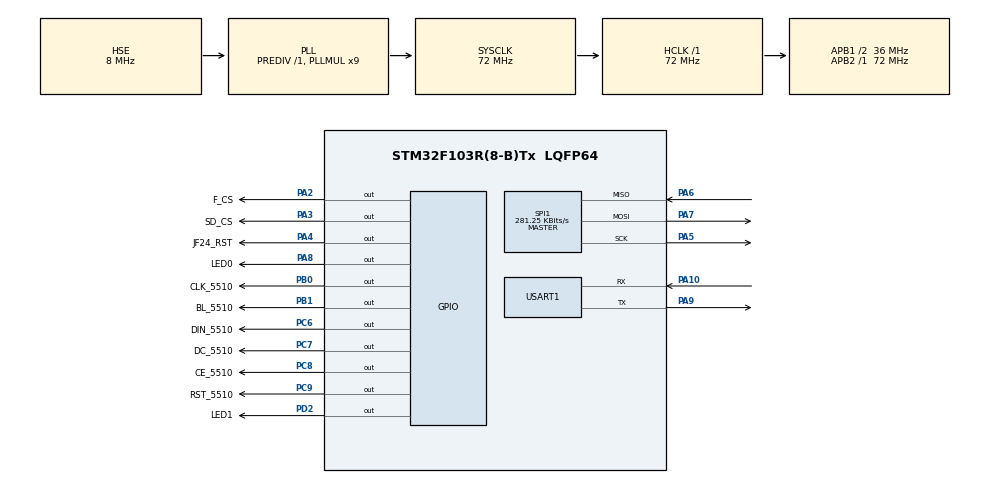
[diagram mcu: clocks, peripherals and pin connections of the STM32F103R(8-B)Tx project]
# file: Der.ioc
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FREERTOS.Tasks01=Task_LED,0,128,Task_Func,Default
Mcu.Family=STM32F1
Mcu.Name=STM32F103R(8-B)Tx
Mcu.Package=LQFP64
NVIC.PriorityGroup=NVIC_PRIORITYGROUP_4
NVIC.TIM4_IRQn=true\:0\:0\:false\:false\:true\:false
NVIC.TimeBase=TIM4_IRQn
NVIC.TimeBaseIP=TIM4
NVIC.USART1_IRQn=true\:0\:0\:false\:false\:true\:false
PA10.Mode=Asynchronous
PA10.Signal=USART1_RX
PA2.GPIO_Label=F_CS
PA2.PinState=GPIO_PIN_SET
PA2.Signal=GPIO_Output
PA3.GPIO_Label=SD_CS
PA3.PinState=GPIO_PIN_SET
PA3.Signal=GPIO_Output
PA4.GPIO_Label=JF24_RST
PA4.PinState=GPIO_PIN_SET
PA4.Signal=GPIO_Output
PA5.Mode=Full_Duplex_Master
PA5.Signal=SPI1_SCK
PA6.Mode=Full_Duplex_Master
PA6.Signal=SPI1_MISO
PA7.Mode=Full_Duplex_Master
PA7.Signal=SPI1_MOSI
PA8.GPIO_Label=LED0
PA8.Signal=GPIO_Output
PA9.Mode=Asynchronous
PA9.Signal=USART1_TX
PB0.GPIO_Label=CLK_5510
PB0.Signal=GPIO_Output
PB1.GPIO_Label=BL_5510
PB1.Signal=GPIO_Output
PC6.GPIO_Label=DIN_5510
PC6.Signal=GPIO_Output
PC7.GPIO_Label=DC_5510
PC7.Signal=GPIO_Output
PC8.GPIO_Label=CE_5510
PC8.Signal=GPIO_Output
PC9.GPIO_Label=RST_5510
PC9.Signal=GPIO_Output
PD0-OSC_IN.Mode=HSE-External-Oscillator
PD0-OSC_IN.Signal=RCC_OSC_IN
PD1-OSC_OUT.Mode=HSE-External-Oscillator
PD1-OSC_OUT.Signal=RCC_OSC_OUT
PD2.GPIO_Label=LED1
PD2.Signal=GPIO_Output
ProjectManager.HeapSize=0x200
ProjectManager.StackSize=0x400
ProjectManager.TargetToolchain=MDK-ARM V5
RCC.AHBFreq_Value=72000000
RCC.APB1CLKDivider=RCC_HCLK_DIV2
RCC.APB1Freq_Value=36000000
RCC.APB1TimFreq_Value=72000000
RCC.APB2Freq_Value=72000000
RCC.APB2TimFreq_Value=72000000
RCC.HCLKFreq_Value=72000000
RCC.HSIState=RCC_HSI_ON
RCC.PLLMUL=RCC_PLL_MUL9
RCC.PLLSourceVirtual=RCC_PLLSOURCE_HSE
RCC.SYSCLKFreq_VALUE=72000000
RCC.SYSCLKSource=RCC_SYSCLKSOURCE_PLLCLK
RCC.USBFreq_Value=72000000
SPI1.BaudRatePrescaler=SPI_BAUDRATEPRESCALER_256
SPI1.CLKPhase=SPI_PHASE_2EDGE
SPI1.CLKPolarity=SPI_POLARITY_HIGH
SPI1.CRCCalculation=SPI_CRCCALCULATION_DISABLE
SPI1.CalculateBaudRate=281.25 KBits/s
SPI1.Mode=SPI_MODE_MASTER
VP_FATFS_VS_Generic.Mode=User_defined
VP_FREERTOS_VS_ENABLE.Mode=Enabled
VP_SYS_VS_ND.Mode=No_Debug
VP_SYS_VS_tim4.Mode=TIM4
board=Der

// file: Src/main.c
/**
  ******************************************************************************
  * File Name          : main.c
  * Description        : Main program body
  ******************************************************************************
  *
  * Copyright (c) 2017 STMicroelectronics International N.V.
  * All rights reserved.
  *
  * Redistribution and use in source and binary forms, with or without
  * modification, are permitted, provided that the following conditions are met:
  *
  * 1. Redistribution of source code must retain the above copyright notice,
  *    this list of conditions and the following disclaimer.
  * 2. Redistributions in binary form must reproduce the above copyright notice,
  *    this list of conditions and the following disclaimer in the documentation
  *    and/or other materials provided with the distribution.
  * 3. Neither the name of STMicroelectronics nor the names of other
  *    contributors to this software may be used to endorse or promote products
  *    derived from this software without specific written permission.
  * 4. This software, including modifications and/or derivative works of this
  *    software, must execute solely and exclusively on microcontroller or
  *    microprocessor devices manufactured by or for STMicroelectronics.
  * 5. Redistribution and use of this software other than as permitted under
  *    this license is void and will automatically terminate your rights under
  *    this license.
  *
  * THIS SOFTWARE IS PROVIDED BY STMICROELECTRONICS AND CONTRIBUTORS "AS IS"
  * AND ANY EXPRESS, IMPLIED OR STATUTORY WARRANTIES, INCLUDING, BUT NOT
  * LIMITED TO, THE IMPLIED WARRANTIES OF MERCHANTABILITY, FITNESS FOR A
  * PARTICULAR PURPOSE AND NON-INFRINGEMENT OF THIRD PARTY INTELLECTUAL PROPERTY
  * RIGHTS ARE DISCLAIMED TO THE FULLEST EXTENT PERMITTED BY LAW. IN NO EVENT
  * SHALL STMICROELECTRONICS OR CONTRIBUTORS BE LIABLE FOR ANY DIRECT, INDIRECT,
  * INCIDENTAL, SPECIAL, EXEMPLARY, OR CONSEQUENTIAL DAMAGES (INCLUDING, BUT NOT
  * LIMITED TO, PROCUREMENT OF SUBSTITUTE GOODS OR SERVICES; LOSS OF USE, DATA,
  * OR PROFITS; OR BUSINESS INTERRUPTION) HOWEVER CAUSED AND ON ANY THEORY OF
  * LIABILITY, WHETHER IN CONTRACT, STRICT LIABILITY, OR TORT (INCLUDING
  * NEGLIGENCE OR OTHERWISE) ARISING IN ANY WAY OUT OF THE USE OF THIS SOFTWARE,
  * EVEN IF ADVISED OF THE POSSIBILITY OF SUCH DAMAGE.
  *
  ******************************************************************************
  */
#include "main.h"
#include "stm32f1xx_hal.h"
#include "cmsis_os.h"
#include "fatfs.h"

/* USER CODE BEGIN Includes */
#include "task_main.h"
#include "defs.h"
/* USER CODE END Includes */

SPI_HandleTypeDef hspi1;

UART_HandleTypeDef huart1;

osThreadId Task_LEDHandle;

void SystemClock_Config(void);
void Error_Handler(void);
static void MX_GPIO_Init(void);
static void MX_USART1_UART_Init(void);
static void MX_SPI1_Init(void);
void Task_Func(void const * argument);

/* USER CODE BEGIN PFP */
/* Private function prototypes -----------------------------------------------*/

/* USER CODE END PFP */

int main(void)
{

  /* MCU Configuration----------------------------------------------------------*/

  /* Reset of all peripherals, Initializes the Flash interface and the Systick. */
  HAL_Init();

  /* Configure the system clock */
  SystemClock_Config();

  /* Initialize all configured peripherals */
  MX_GPIO_Init();
  MX_USART1_UART_Init();
  MX_SPI1_Init();

  /* Create the thread(s) */
  /* definition and creation of Task_LED */
//  osThreadDef(Task_LED, Task_Func, osPriorityNormal, 0, 128);
//  Task_LEDHandle = osThreadCreate(osThread(Task_LED), NULL);

  /* USER CODE BEGIN RTOS_QUEUES */
  /* add queues, ... */
    thread_init();
  /* USER CODE END RTOS_QUEUES */

  /* Start scheduler */
  osKernelStart();

  /* We should never get here as control is now taken by the scheduler */

  /* Infinite loop */
  while (1)
  {

  }

}

/** System Clock Configuration
*/
void SystemClock_Config(void)
{

  RCC_OscInitTypeDef RCC_OscInitStruct;
  RCC_ClkInitTypeDef RCC_ClkInitStruct;

    /**Initializes the CPU, AHB and APB busses clocks
    */
  RCC_OscInitStruct.OscillatorType = RCC_OSCILLATORTYPE_HSE;
  RCC_OscInitStruct.HSEState = RCC_HSE_ON;
  RCC_OscInitStruct.HSEPredivValue = RCC_HSE_PREDIV_DIV1;
  RCC_OscInitStruct.HSIState = RCC_HSI_ON;
  RCC_OscInitStruct.PLL.PLLState = RCC_PLL_ON;
  RCC_OscInitStruct.PLL.PLLSource = RCC_PLLSOURCE_HSE;
  RCC_OscInitStruct.PLL.PLLMUL = RCC_PLL_MUL9;
  if (HAL_RCC_OscConfig(&RCC_OscInitStruct) != HAL_OK)
  {
    Error_Handler();
  }

    /**Initializes the CPU, AHB and APB busses clocks
    */
  RCC_ClkInitStruct.ClockType = RCC_CLOCKTYPE_HCLK|RCC_CLOCKTYPE_SYSCLK
                              |RCC_CLOCKTYPE_PCLK1|RCC_CLOCKTYPE_PCLK2;
  RCC_ClkInitStruct.SYSCLKSource = RCC_SYSCLKSOURCE_PLLCLK;
  RCC_ClkInitStruct.AHBCLKDivider = RCC_SYSCLK_DIV1;
  RCC_ClkInitStruct.APB1CLKDivider = RCC_HCLK_DIV2;
  RCC_ClkInitStruct.APB2CLKDivider = RCC_HCLK_DIV1;

  if (HAL_RCC_ClockConfig(&RCC_ClkInitStruct, FLASH_LATENCY_2) != HAL_OK)
  {
    Error_Handler();
  }

    /**Configure the Systick interrupt time
    */
  HAL_SYSTICK_Config(HAL_RCC_GetHCLKFreq()/1000);

    /**Configure the Systick
    */
  HAL_SYSTICK_CLKSourceConfig(SYSTICK_CLKSOURCE_HCLK);

  /* SysTick_IRQn interrupt configuration */
  HAL_NVIC_SetPriority(SysTick_IRQn, 15, 0);
}

/* SPI1 init function */
static void MX_SPI1_Init(void)
{

  hspi1.Instance = SPI1;
  hspi1.Init.Mode = SPI_MODE_MASTER;
  hspi1.Init.Direction = SPI_DIRECTION_2LINES;
  hspi1.Init.DataSize = SPI_DATASIZE_8BIT;
  hspi1.Init.CLKPolarity = SPI_POLARITY_HIGH;
  hspi1.Init.CLKPhase = SPI_PHASE_2EDGE;
  hspi1.Init.NSS = SPI_NSS_SOFT;
  hspi1.Init.BaudRatePrescaler = SPI_BAUDRATEPRESCALER_256;
  hspi1.Init.FirstBit = SPI_FIRSTBIT_MSB;
  hspi1.Init.TIMode = SPI_TIMODE_DISABLE;
  hspi1.Init.CRCCalculation = SPI_CRCCALCULATION_DISABLE;
  hspi1.Init.CRCPolynomial = 7;
  if (HAL_SPI_Init(&hspi1) != HAL_OK)
  {
    Error_Handler();
  }

}

/* USART1 init function */
static void MX_USART1_UART_Init(void)
{

  huart1.Instance = USART1;
  huart1.Init.BaudRate = 115200;
  huart1.Init.WordLength = UART_WORDLENGTH_8B;
  huart1.Init.StopBits = UART_STOPBITS_1;
  huart1.Init.Parity = UART_PARITY_NONE;
  huart1.Init.Mode = UART_MODE_TX_RX;
  huart1.Init.HwFlowCtl = UART_HWCONTROL_NONE;
  huart1.Init.OverSampling = UART_OVERSAMPLING_16;
  if (HAL_UART_Init(&huart1) != HAL_OK)
  {
    Error_Handler();
  }

}

/** Configure pins as
        * Analog
        * Input
        * Output
        * EVENT_OUT
        * EXTI
*/
static void MX_GPIO_Init(void)
{

  GPIO_InitTypeDef GPIO_InitStruct;

  /* GPIO Ports Clock Enable */
  __HAL_RCC_GPIOD_CLK_ENABLE();
  __HAL_RCC_GPIOA_CLK_ENABLE();
  __HAL_RCC_GPIOB_CLK_ENABLE();
  __HAL_RCC_GPIOC_CLK_ENABLE();

  /*Configure GPIO pin Output Level */
  HAL_GPIO_WritePin(GPIOA, F_CS_Pin|SD_CS_Pin|JF24_RST_Pin, GPIO_PIN_SET);

  /*Configure GPIO pin Output Level */
  HAL_GPIO_WritePin(GPIOB, CLK_5510_Pin|BL_5510_Pin, GPIO_PIN_RESET);

  /*Configure GPIO pin Output Level */
  HAL_GPIO_WritePin(GPIOC, DIN_5510_Pin|DC_5510_Pin|CE_5510_Pin|RST_5510_Pin, GPIO_PIN_RESET);

  /*Configure GPIO pin Output Level */
  HAL_GPIO_WritePin(LED0_GPIO_Port, LED0_Pin, GPIO_PIN_RESET);

  /*Configure GPIO pin Output Level */
  HAL_GPIO_WritePin(LED1_GPIO_Port, LED1_Pin, GPIO_PIN_RESET);

  /*Configure GPIO pins : F_CS_Pin SD_CS_Pin JF24_RST_Pin LED0_Pin */
  GPIO_InitStruct.Pin = F_CS_Pin|SD_CS_Pin|JF24_RST_Pin|LED0_Pin;
  GPIO_InitStruct.Mode = GPIO_MODE_OUTPUT_PP;
  GPIO_InitStruct.Speed = GPIO_SPEED_FREQ_LOW;
  HAL_GPIO_Init(GPIOA, &GPIO_InitStruct);

  /*Configure GPIO pins : CLK_5510_Pin BL_5510_Pin */
  GPIO_InitStruct.Pin = CLK_5510_Pin|BL_5510_Pin;
  GPIO_InitStruct.Mode = GPIO_MODE_OUTPUT_PP;
  GPIO_InitStruct.Speed = GPIO_SPEED_FREQ_LOW;
  HAL_GPIO_Init(GPIOB, &GPIO_InitStruct);

  /*Configure GPIO pins : DIN_5510_Pin DC_5510_Pin CE_5510_Pin RST_5510_Pin */
  GPIO_InitStruct.Pin = DIN_5510_Pin|DC_5510_Pin|CE_5510_Pin|RST_5510_Pin;
  GPIO_InitStruct.Mode = GPIO_MODE_OUTPUT_PP;
  GPIO_InitStruct.Speed = GPIO_SPEED_FREQ_LOW;
  HAL_GPIO_Init(GPIOC, &GPIO_InitStruct);

  /*Configure GPIO pin : LED1_Pin */
  GPIO_InitStruct.Pin = LED1_Pin;
  GPIO_InitStruct.Mode = GPIO_MODE_OUTPUT_PP;
  GPIO_InitStruct.Speed = GPIO_SPEED_FREQ_LOW;
  HAL_GPIO_Init(LED1_GPIO_Port, &GPIO_InitStruct);

}

/* Task_Func function */
void Task_Func(void const * argument)
{
  /* init code for FATFS */
  MX_FATFS_Init();

  for(;;)
  {
    osDelay(1);
  }
}

void HAL_TIM_PeriodElapsedCallback(TIM_HandleTypeDef *htim)
{
  if (htim->Instance == TIM4) {
    HAL_IncTick();
  }
}

void Error_Handler(void)
{
  while(1)
  {
  }
}

/************************ (C) COPYRIGHT STMicroelectronics *****END OF FILE****/
